# Espressif register map
File version: 1.0
CPU: Xtensa LX6 1, little endian, no MPU, FPU, 3 interrupt priority bits
Registers are 32-bit, access not given, reset 0x0 unless marked. A register's access mark holds for its fields unless they carry their own. Offsets are from the block's base; [hi:lo] are bit positions; {n}, {i} and the like mark numbered series.

## UHCI
Base 0x00000000
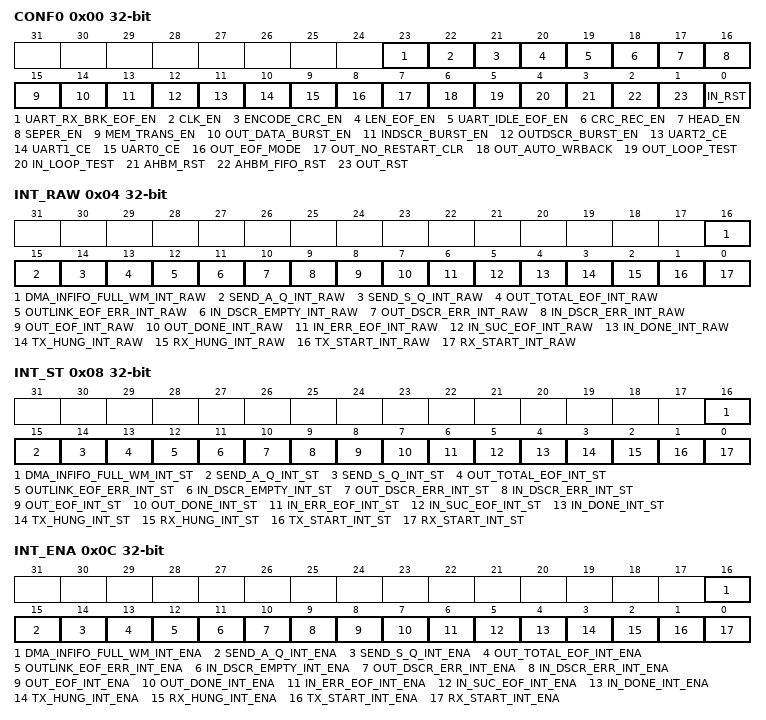
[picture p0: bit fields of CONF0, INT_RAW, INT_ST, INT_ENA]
0x00 CONF0 — UHCI_CONF0
  [23] UART_RX_BRK_EOF_EN, [22] CLK_EN, [21] ENCODE_CRC_EN, [20] LEN_EOF_EN, [19] UART_IDLE_EOF_EN, [18] CRC_REC_EN, [17] HEAD_EN, [16] SEPER_EN, [15] MEM_TRANS_EN, [14] OUT_DATA_BURST_EN, [13] INDSCR_BURST_EN, [12] OUTDSCR_BURST_EN, [11] UART2_CE, [10] UART1_CE, [9] UART0_CE, [8] OUT_EOF_MODE, [7] OUT_NO_RESTART_CLR, [6] OUT_AUTO_WRBACK, [5] OUT_LOOP_TEST, [4] IN_LOOP_TEST, [3] AHBM_RST, [2] AHBM_FIFO_RST, [1] OUT_RST, [0] IN_RST
0x04 INT_RAW — UHCI_INT_RAW
  [16] DMA_INFIFO_FULL_WM_INT_RAW, [15] SEND_A_Q_INT_RAW, [14] SEND_S_Q_INT_RAW, [13] OUT_TOTAL_EOF_INT_RAW, [12] OUTLINK_EOF_ERR_INT_RAW, [11] IN_DSCR_EMPTY_INT_RAW, [10] OUT_DSCR_ERR_INT_RAW, [9] IN_DSCR_ERR_INT_RAW, [8] OUT_EOF_INT_RAW, [7] OUT_DONE_INT_RAW, [6] IN_ERR_EOF_INT_RAW, [5] IN_SUC_EOF_INT_RAW, [4] IN_DONE_INT_RAW, [3] TX_HUNG_INT_RAW, [2] RX_HUNG_INT_RAW, [1] TX_START_INT_RAW, [0] RX_START_INT_RAW
0x08 INT_ST — UHCI_INT_ST
  [16] DMA_INFIFO_FULL_WM_INT_ST, [15] SEND_A_Q_INT_ST, [14] SEND_S_Q_INT_ST, [13] OUT_TOTAL_EOF_INT_ST, [12] OUTLINK_EOF_ERR_INT_ST, [11] IN_DSCR_EMPTY_INT_ST, [10] OUT_DSCR_ERR_INT_ST, [9] IN_DSCR_ERR_INT_ST, [8] OUT_EOF_INT_ST, [7] OUT_DONE_INT_ST, [6] IN_ERR_EOF_INT_ST, [5] IN_SUC_EOF_INT_ST, [4] IN_DONE_INT_ST, [3] TX_HUNG_INT_ST, [2] RX_HUNG_INT_ST, [1] TX_START_INT_ST, [0] RX_START_INT_ST
0x0C INT_ENA — UHCI_INT_ENA
  [16] DMA_INFIFO_FULL_WM_INT_ENA, [15] SEND_A_Q_INT_ENA, [14] SEND_S_Q_INT_ENA, [13] OUT_TOTAL_EOF_INT_ENA, [12] OUTLINK_EOF_ERR_INT_ENA, [11] IN_DSCR_EMPTY_INT_ENA, [10] OUT_DSCR_ERR_INT_ENA, [9] IN_DSCR_ERR_INT_ENA, [8] OUT_EOF_INT_ENA, [7] OUT_DONE_INT_ENA, [6] IN_ERR_EOF_INT_ENA, [5] IN_SUC_EOF_INT_ENA, [4] IN_DONE_INT_ENA, [3] TX_HUNG_INT_ENA, [2] RX_HUNG_INT_ENA, [1] TX_START_INT_ENA, [0] RX_START_INT_ENA
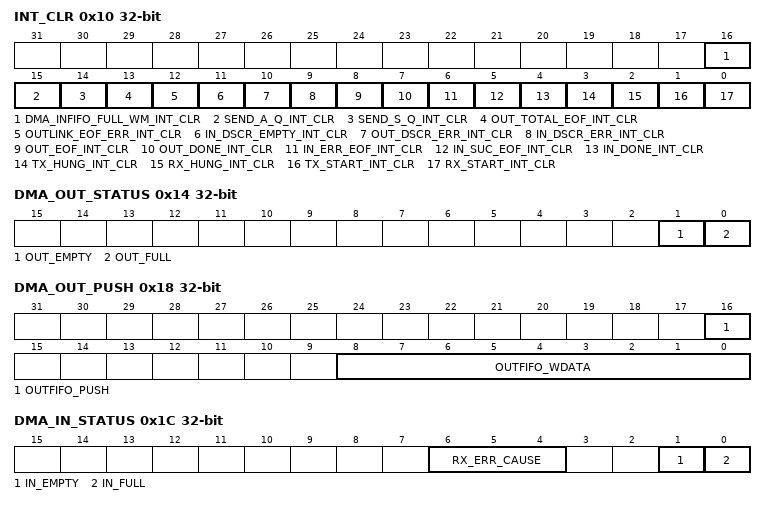
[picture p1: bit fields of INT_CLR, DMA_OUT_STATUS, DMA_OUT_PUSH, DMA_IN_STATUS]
0x10 INT_CLR — UHCI_INT_CLR
  [16] DMA_INFIFO_FULL_WM_INT_CLR, [15] SEND_A_Q_INT_CLR, [14] SEND_S_Q_INT_CLR, [13] OUT_TOTAL_EOF_INT_CLR, [12] OUTLINK_EOF_ERR_INT_CLR, [11] IN_DSCR_EMPTY_INT_CLR, [10] OUT_DSCR_ERR_INT_CLR, [9] IN_DSCR_ERR_INT_CLR, [8] OUT_EOF_INT_CLR, [7] OUT_DONE_INT_CLR, [6] IN_ERR_EOF_INT_CLR, [5] IN_SUC_EOF_INT_CLR, [4] IN_DONE_INT_CLR, [3] TX_HUNG_INT_CLR, [2] RX_HUNG_INT_CLR, [1] TX_START_INT_CLR, [0] RX_START_INT_CLR
0x14 DMA_OUT_STATUS — UHCI_DMA_OUT_STATUS
  [1] OUT_EMPTY, [0] OUT_FULL
0x18 DMA_OUT_PUSH — UHCI_DMA_OUT_PUSH
  [16] OUTFIFO_PUSH, [8:0] OUTFIFO_WDATA
0x1C DMA_IN_STATUS — UHCI_DMA_IN_STATUS
  [6:4] RX_ERR_CAUSE, [1] IN_EMPTY, [0] IN_FULL
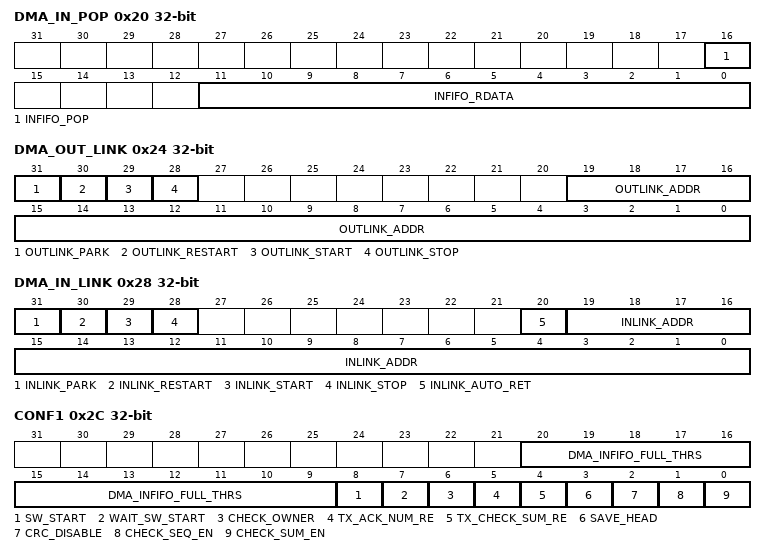
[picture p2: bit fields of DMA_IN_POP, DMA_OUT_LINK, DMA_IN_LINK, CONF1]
0x20 DMA_IN_POP — UHCI_DMA_IN_POP
  [16] INFIFO_POP, [11:0] INFIFO_RDATA
0x24 DMA_OUT_LINK — UHCI_DMA_OUT_LINK
  [31] OUTLINK_PARK, [30] OUTLINK_RESTART, [29] OUTLINK_START, [28] OUTLINK_STOP, [19:0] OUTLINK_ADDR
0x28 DMA_IN_LINK — UHCI_DMA_IN_LINK
  [31] INLINK_PARK, [30] INLINK_RESTART, [29] INLINK_START, [28] INLINK_STOP, [20] INLINK_AUTO_RET, [19:0] INLINK_ADDR
0x2C CONF1 — UHCI_CONF1
  [20:9] DMA_INFIFO_FULL_THRS, [8] SW_START, [7] WAIT_SW_START, [6] CHECK_OWNER, [5] TX_ACK_NUM_RE, [4] TX_CHECK_SUM_RE, [3] SAVE_HEAD, [2] CRC_DISABLE, [1] CHECK_SEQ_EN, [0] CHECK_SUM_EN
0x30 STATE0 — UHCI_STATE0
0x34 STATE1 — UHCI_STATE1
0x38 DMA_OUT_EOF_DES_ADDR — UHCI_DMA_OUT_EOF_DES_ADDR
  [31:0] OUT_EOF_DES_ADDR
0x3C DMA_IN_SUC_EOF_DES_ADDR — UHCI_DMA_IN_SUC_EOF_DES_ADDR
  [31:0] IN_SUC_EOF_DES_ADDR
0x40 DMA_IN_ERR_EOF_DES_ADDR — UHCI_DMA_IN_ERR_EOF_DES_ADDR
  [31:0] IN_ERR_EOF_DES_ADDR
0x44 DMA_OUT_EOF_BFR_DES_ADDR — UHCI_DMA_OUT_EOF_BFR_DES_ADDR
  [31:0] OUT_EOF_BFR_DES_ADDR
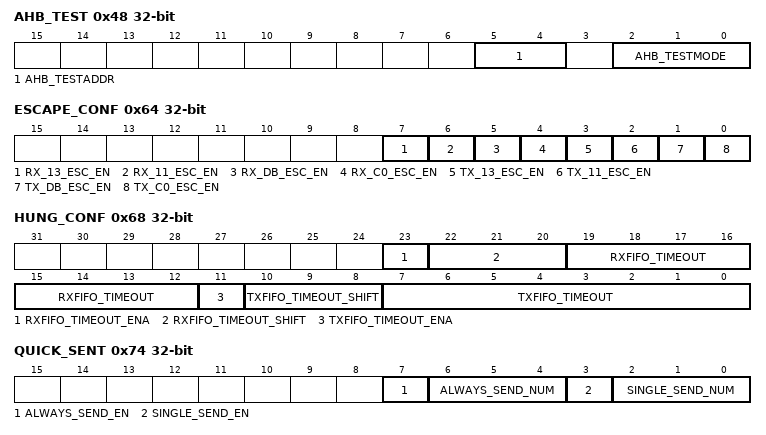
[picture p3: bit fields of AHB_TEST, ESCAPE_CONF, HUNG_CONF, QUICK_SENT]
0x48 AHB_TEST — UHCI_AHB_TEST
  [5:4] AHB_TESTADDR, [2:0] AHB_TESTMODE
0x4C DMA_IN_DSCR — UHCI_DMA_IN_DSCR
  [31:0] INLINK_DSCR
0x50 DMA_IN_DSCR_BF0 — UHCI_DMA_IN_DSCR_BF0
  [31:0] INLINK_DSCR_BF0
0x54 DMA_IN_DSCR_BF1 — UHCI_DMA_IN_DSCR_BF1
  [31:0] INLINK_DSCR_BF1
0x58 DMA_OUT_DSCR — UHCI_DMA_OUT_DSCR
  [31:0] OUTLINK_DSCR
0x5C DMA_OUT_DSCR_BF0 — UHCI_DMA_OUT_DSCR_BF0
  [31:0] OUTLINK_DSCR_BF0
0x60 DMA_OUT_DSCR_BF1 — UHCI_DMA_OUT_DSCR_BF1
  [31:0] OUTLINK_DSCR_BF1
0x64 ESCAPE_CONF — UHCI_ESCAPE_CONF
  [7] RX_13_ESC_EN, [6] RX_11_ESC_EN, [5] RX_DB_ESC_EN, [4] RX_C0_ESC_EN, [3] TX_13_ESC_EN, [2] TX_11_ESC_EN, [1] TX_DB_ESC_EN, [0] TX_C0_ESC_EN
0x68 HUNG_CONF — UHCI_HUNG_CONF
  [23] RXFIFO_TIMEOUT_ENA, [22:20] RXFIFO_TIMEOUT_SHIFT, [19:12] RXFIFO_TIMEOUT, [11] TXFIFO_TIMEOUT_ENA, [10:8] TXFIFO_TIMEOUT_SHIFT, [7:0] TXFIFO_TIMEOUT
0x70 RX_HEAD — UHCI_RX_HEAD
0x74 QUICK_SENT — UHCI_QUICK_SENT
  [7] ALWAYS_SEND_EN, [6:4] ALWAYS_SEND_NUM, [3] SINGLE_SEND_EN, [2:0] SINGLE_SEND_NUM
{0x78+8i} Q{i}_WORD0 (i=0..6) — UHCI_Q{i}_WORD0
  [31:0] SEND_Q{i}_WORD0
{0x7C+8i} Q{i}_WORD1 (i=0..6) — UHCI_Q{i}_WORD1
  [31:0] SEND_Q{i}_WORD1
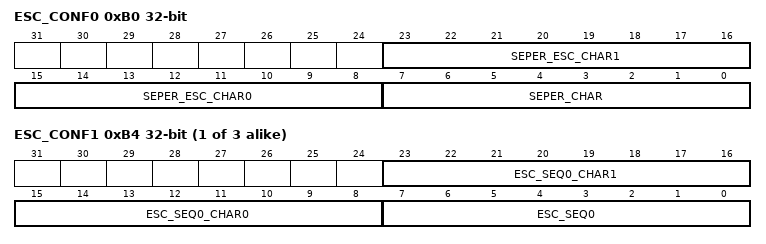
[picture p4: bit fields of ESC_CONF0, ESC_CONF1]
0xB0 ESC_CONF0 — UHCI_ESC_CONF0
  [23:16] SEPER_ESC_CHAR1, [15:8] SEPER_ESC_CHAR0, [7:0] SEPER_CHAR
{0xB0+4i} ESC_CONF{i} (i=1..3) — UHCI_ESC_CONF{i}
  [23:16] ESC_SEQ{i-1}_CHAR1, [15:8] ESC_SEQ{i-1}_CHAR0, [7:0] ESC_SEQ{i-1}
0xC0 PKT_THRES — UHCI_PKT_THRES
  [12:0] PKT_THRS
0xFC DATE — UHCI_DATE
